# pktdma_tx register map
Vendor: Texas Instruments
Peripheral module from a debugger description file (folder pktdma).
Registers are 32-bit, read-write, no defined reset value unless marked. A register's access mark holds for its fields unless they carry their own. Offsets are as the file gives them; lines under a group give offsets from that group; [hi:lo] are bit positions; {n}, {i} and the like mark numbered series; 'fields as' and 'values as' point back to an identical list; <NAME> marks a mode.

## SRIO_PKTDMA_TX
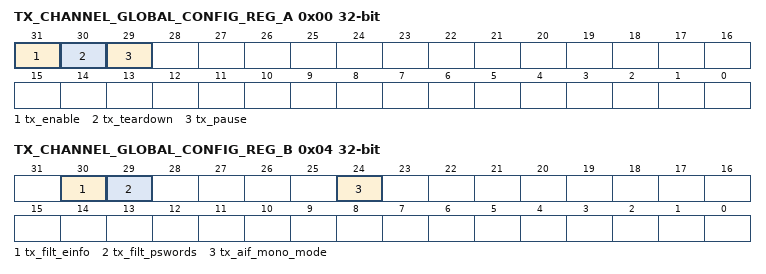
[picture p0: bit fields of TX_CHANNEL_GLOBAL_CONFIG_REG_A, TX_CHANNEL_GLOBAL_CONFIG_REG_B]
0x00 TX_CHANNEL_GLOBAL_CONFIG_REG_A — (1 of 129, stride 32)
  [31] tx_enable — Tx channel enable: 0=Channel is disabled, 1=Channel is enabled
  [30] tx_teardown — Setting this bit will request the channel to be torn down
  [29] tx_pause — Setting this bit will request the channel to pause processing at the next packet boundary
0x04 TX_CHANNEL_GLOBAL_CONFIG_REG_B wo — (1 of 129, stride 32)
  [30] tx_filt_einfo — This field controls whether or not the DMA controller will pass the extended packet information fields, if present, from the descriptor to the back end application
  [29] tx_filt_pswords — This field controls whether or not the DMA controller will pass the protocol specific words, if present, from the descriptor to the back end application
  [24] tx_aif_mono_mode — This field when set indicates that all monolithic packets which will be transferred on this channel will be formatted in an optimal configuration as needed by the Antenna Interface Peripheral
